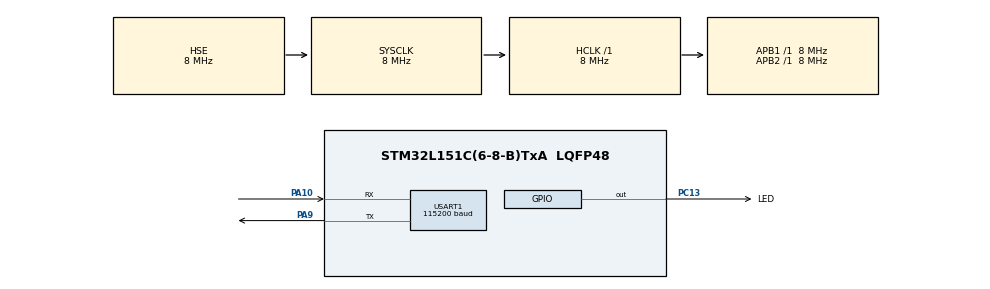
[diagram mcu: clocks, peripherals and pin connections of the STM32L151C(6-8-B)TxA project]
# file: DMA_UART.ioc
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Dma.Request0=USART1_RX
Dma.Request1=USART1_TX
Dma.USART1_RX.0.Direction=DMA_PERIPH_TO_MEMORY
Dma.USART1_RX.0.Instance=DMA1_Channel5
Dma.USART1_RX.0.MemDataAlignment=DMA_MDATAALIGN_BYTE
Dma.USART1_RX.0.MemInc=DMA_MINC_ENABLE
Dma.USART1_RX.0.Mode=DMA_NORMAL
Dma.USART1_RX.0.PeriphDataAlignment=DMA_PDATAALIGN_BYTE
Dma.USART1_RX.0.PeriphInc=DMA_PINC_DISABLE
Dma.USART1_RX.0.Priority=DMA_PRIORITY_MEDIUM
Dma.USART1_TX.1.Direction=DMA_MEMORY_TO_PERIPH
Dma.USART1_TX.1.Instance=DMA1_Channel4
Dma.USART1_TX.1.MemDataAlignment=DMA_MDATAALIGN_BYTE
Dma.USART1_TX.1.MemInc=DMA_MINC_ENABLE
Dma.USART1_TX.1.Mode=DMA_NORMAL
Dma.USART1_TX.1.PeriphDataAlignment=DMA_PDATAALIGN_BYTE
Dma.USART1_TX.1.PeriphInc=DMA_PINC_DISABLE
Dma.USART1_TX.1.Priority=DMA_PRIORITY_MEDIUM
Mcu.Family=STM32L1
Mcu.Name=STM32L151C(6-8-B)TxA
Mcu.Package=LQFP48
NVIC.DMA1_Channel4_IRQn=true\:1\:0\:true\:false\:true\:false\:true\:true
NVIC.DMA1_Channel5_IRQn=true\:1\:0\:true\:false\:true\:false\:true\:true
NVIC.PriorityGroup=NVIC_PRIORITYGROUP_4
NVIC.USART1_IRQn=true\:1\:0\:true\:false\:true\:false\:true\:true
PA10.Mode=Asynchronous
PA10.Signal=USART1_RX
PA13.Mode=Serial_Wire
PA13.Signal=SYS_JTMS-SWDIO
PA14.Mode=Serial_Wire
PA14.Signal=SYS_JTCK-SWCLK
PA9.Mode=Asynchronous
PA9.Signal=USART1_TX
PC13-WKUP2.GPIO_Label=LED
PC13-WKUP2.GPIO_ModeDefaultOutputPP=GPIO_MODE_OUTPUT_OD
PC13-WKUP2.GPIO_PuPd=GPIO_NOPULL
PC13-WKUP2.GPIO_Speed=GPIO_SPEED_FREQ_LOW
PC13-WKUP2.PinState=GPIO_PIN_SET
PC13-WKUP2.Signal=GPIO_Output
PH0-OSC_IN.Mode=HSE-External-Oscillator
PH0-OSC_IN.Signal=RCC_OSC_IN
PH1-OSC_OUT.Mode=HSE-External-Oscillator
PH1-OSC_OUT.Signal=RCC_OSC_OUT
ProjectManager.HeapSize=0x200
ProjectManager.StackSize=0x400
ProjectManager.TargetToolchain=MDK-ARM V5.32
RCC.48MHZClocksFreq_Value=12000000
RCC.AHBFreq_Value=8000000
RCC.APB1Freq_Value=8000000
RCC.APB1TimFreq_Value=8000000
RCC.APB2Freq_Value=8000000
RCC.APB2TimFreq_Value=8000000
RCC.HCLKFreq_Value=8000000
RCC.HSE_VALUE=8000000
RCC.HSI_VALUE=16000000
RCC.LSE_VALUE=32768
RCC.MSI_VALUE=2097000
RCC.PLLSourceVirtual=RCC_PLLSOURCE_HSE
RCC.SYSCLKFreq_VALUE=8000000
RCC.SYSCLKSource=RCC_SYSCLKSOURCE_HSE
RCC.VCOOutputFreq_Value=24000000
USART1.BaudRate=115200
USART1.VirtualMode=VM_ASYNC
board=custom

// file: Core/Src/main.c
/* USER CODE BEGIN Header */
/**
  ******************************************************************************
  * @file           : main.c
  * @brief          : Main program body
  ******************************************************************************
  * @attention
  *
  * Copyright (c) 2026 STMicroelectronics.
  * All rights reserved.
  *
  * This software is licensed under terms that can be found in the LICENSE file
  * in the root directory of this software component.
  * If no LICENSE file comes with this software, it is provided AS-IS.
  *
  ******************************************************************************
  */
/* USER CODE END Header */
#include "main.h"
#include "dma.h"
#include "usart.h"
#include "gpio.h"

/* USER CODE BEGIN PD */
#define Bufflen 2
/* USER CODE END PD */

/* USER CODE BEGIN PV */
uint8_t ReceiveBuff[Bufflen];
uint8_t hello[5]={0x48,0x65,0x6c,0x6f,0x77};
uint8_t clear=RESET;
/* USER CODE END PV */

void SystemClock_Config(void);

int main(void)
{

  /* MCU Configuration--------------------------------------------------------*/

  /* Reset of all peripherals, Initializes the Flash interface and the Systick. */
  HAL_Init();

  /* Configure the system clock */
  SystemClock_Config();

  /* Initialize all configured peripherals */
  MX_GPIO_Init();
  MX_DMA_Init();
  MX_USART1_UART_Init();
  /* USER CODE BEGIN 2 */
	HAL_UART_Transmit_DMA(&huart1,hello,5);
	HAL_UART_Receive_DMA(&huart1,ReceiveBuff,Bufflen);
  /* USER CODE END 2 */

  /* Infinite loop */
  /* USER CODE BEGIN WHILE */
  while (1)
  {
		if(clear==SET)
		{
			HAL_UART_Transmit_DMA(&huart1,ReceiveBuff,Bufflen);
			if(ReceiveBuff[0]=='#')
			{
				if(ReceiveBuff[1]=='A')
				{
					HAL_GPIO_WritePin(GPIOC,GPIO_PIN_13,GPIO_PIN_RESET);
				}else if(ReceiveBuff[1]=='B')
				{
					HAL_GPIO_WritePin(GPIOC,GPIO_PIN_13,GPIO_PIN_SET);
				}
			}
			for(uint8_t i=0;i<2;i++)
			{
				ReceiveBuff[i]=0x00;
			}
			clear=RESET;
			HAL_UART_Receive_DMA(&huart1,ReceiveBuff,Bufflen);
		}
    /* USER CODE END WHILE */

  }
}

void SystemClock_Config(void)
{
  RCC_OscInitTypeDef RCC_OscInitStruct = {0};
  RCC_ClkInitTypeDef RCC_ClkInitStruct = {0};

  /** Configure the main internal regulator output voltage
  */
  __HAL_PWR_VOLTAGESCALING_CONFIG(PWR_REGULATOR_VOLTAGE_SCALE1);

  /** Initializes the RCC Oscillators according to the specified parameters
  * in the RCC_OscInitTypeDef structure.
  */
  RCC_OscInitStruct.OscillatorType = RCC_OSCILLATORTYPE_HSE;
  RCC_OscInitStruct.HSEState = RCC_HSE_ON;
  RCC_OscInitStruct.PLL.PLLState = RCC_PLL_NONE;
  if (HAL_RCC_OscConfig(&RCC_OscInitStruct) != HAL_OK)
  {
    Error_Handler();
  }

  /** Initializes the CPU, AHB and APB buses clocks
  */
  RCC_ClkInitStruct.ClockType = RCC_CLOCKTYPE_HCLK|RCC_CLOCKTYPE_SYSCLK
                              |RCC_CLOCKTYPE_PCLK1|RCC_CLOCKTYPE_PCLK2;
  RCC_ClkInitStruct.SYSCLKSource = RCC_SYSCLKSOURCE_HSE;
  RCC_ClkInitStruct.AHBCLKDivider = RCC_SYSCLK_DIV1;
  RCC_ClkInitStruct.APB1CLKDivider = RCC_HCLK_DIV1;
  RCC_ClkInitStruct.APB2CLKDivider = RCC_HCLK_DIV1;

  if (HAL_RCC_ClockConfig(&RCC_ClkInitStruct, FLASH_LATENCY_0) != HAL_OK)
  {
    Error_Handler();
  }
}

/* USER CODE BEGIN 4 */
void HAL_UART_RxCpltCallback(UART_HandleTypeDef *huart)
{
	if(huart->Instance==USART1)
	{
		clear=SET;
	}
}
/* USER CODE END 4 */

void Error_Handler(void)
{
  __disable_irq();
  while (1)
  {
  }
}
